AUTOSAR XML (schema 4-0-3)
standard types defined: Boolean, uint8, UInt16, UInt32, UInt8
package /AUTOSAR_Platform/DataConstrs
  range DC_Boolean: raw 0..1
  range DC_UInt16: raw 0..65535
  range DC_UInt8: raw 0..255
package /PATAC/Facility/DataTypes/Implementation
  compu method COMPU_Boolean: 0=FALSE, 1=TRUE
  unit NoUnit: factor-si-to-unit=1, offset-si-to-unit=0
package /PATAC/MSM/ComponentTypes
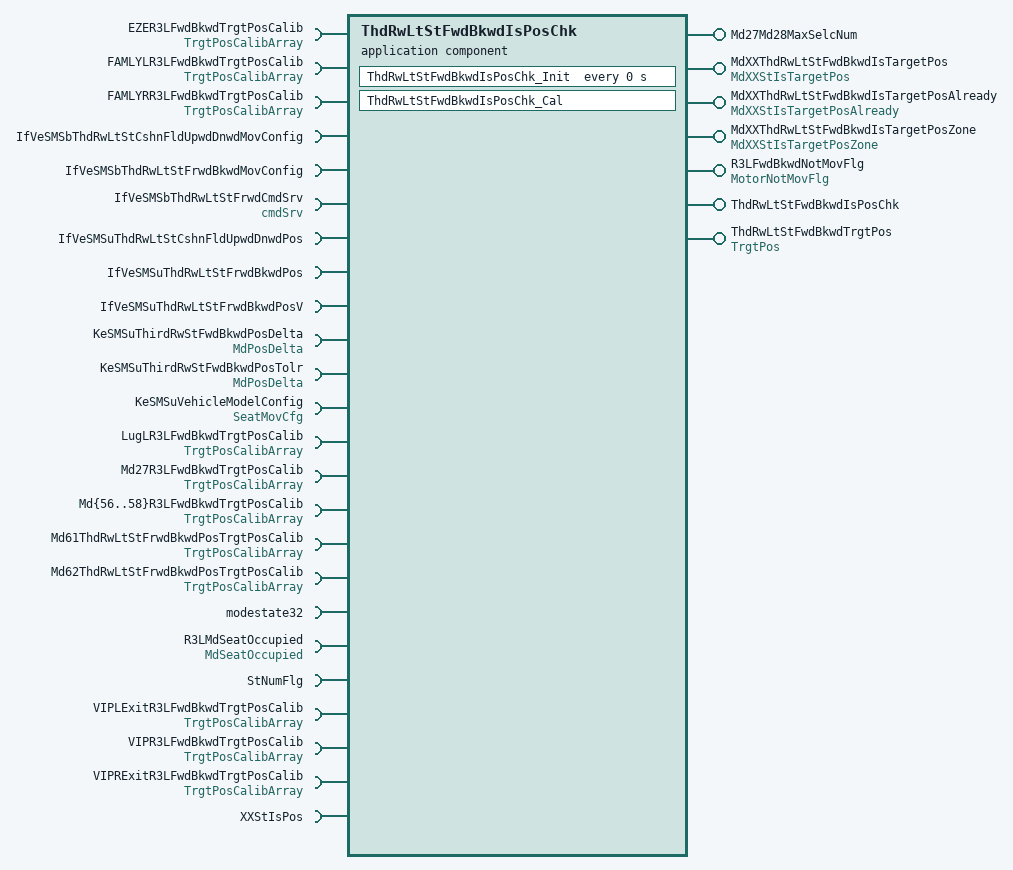
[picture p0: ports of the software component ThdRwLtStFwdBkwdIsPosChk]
  application sw component type ThdRwLtStFwdBkwdIsPosChk
    7 x provide port:
      Md27Md28MaxSelcNum: nonqueued-sender-com-spec{data-element=Md27Md28MaxSelcNum/Val, init-value=0}, provided-interface=Md27Md28MaxSelcNum
      MdXXThdRwLtStFwdBkwdIsTargetPos: nonqueued-sender-com-spec=data-element=MdXXStIsTargetPos/Val, provided-interface=MdXXStIsTargetPos
      MdXXThdRwLtStFwdBkwdIsTargetPosAlready: nonqueued-sender-com-spec=data-element=MdXXStIsTargetPosAlready/Val, provided-interface=MdXXStIsTargetPosAlready
      MdXXThdRwLtStFwdBkwdIsTargetPosZone: nonqueued-sender-com-spec=data-element=MdXXStIsTargetPosZone/Val, provided-interface=MdXXStIsTargetPosZone
      R3LFwdBkwdNotMovFlg: nonqueued-sender-com-spec{data-element=MotorNotMovFlg/Val, init-value=0}, provided-interface=MotorNotMovFlg
      ThdRwLtStFwdBkwdIsPosChk: server-com-spec{operation=Cal, queue-length=1}, provided-interface=ThdRwLtStFwdBkwdIsPosChk
      ThdRwLtStFwdBkwdTrgtPos: nonqueued-sender-com-spec{data-element=TrgtPos/Val, init-value=4095}, provided-interface=TrgtPos
    26 x require port:
      EZER3LFwdBkwdTrgtPosCalib: nonqueued-receiver-com-spec{data-element=TrgtPosArray, filter=data-filter-type=ALWAYS, init-value=[4095, 4095, 4095]}, required-interface=TrgtPosCalibArray
      FAMLYLR3LFwdBkwdTrgtPosCalib: nonqueued-receiver-com-spec{data-element=TrgtPosArray, filter=data-filter-type=ALWAYS, init-value=[4095, 4095, 4095]}, required-interface=TrgtPosCalibArray
      FAMLYRR3LFwdBkwdTrgtPosCalib: nonqueued-receiver-com-spec{data-element=TrgtPosArray, filter=data-filter-type=ALWAYS, init-value=[4095, 4095, 4095]}, required-interface=TrgtPosCalibArray
      IfVeSMSbThdRwLtStCshnFldUpwdDnwdMovConfig: nonqueued-receiver-com-spec{data-element=IfVeSMSbThdRwLtStCshnFldUpwdDnwdMovConfig/Val, filter=data-filter-type=ALWAYS, init-value=0}, required-interface=IfVeSMSbThdRwLtStCshnFldUpwdDnwdMovConfig
      IfVeSMSbThdRwLtStFrwdBkwdMovConfig: nonqueued-receiver-com-spec{data-element=IfVeSMSbThdRwLtStFrwdBkwdMovConfig/Val, filter=data-filter-type=ALWAYS, init-value=0}, required-interface=IfVeSMSbThdRwLtStFrwdBkwdMovConfig
      IfVeSMSbThdRwLtStFrwdCmdSrv: nonqueued-receiver-com-spec{data-element=cmdSrv/Val, filter=data-filter-type=ALWAYS, init-value=1}, required-interface=cmdSrv
      IfVeSMSuThdRwLtStCshnFldUpwdDnwdPos: nonqueued-receiver-com-spec{data-element=IfVeSMSuThdRwLtStCshnFldUpwdDnwdPos/Val, filter=data-filter-type=ALWAYS, init-value=0}, required-interface=IfVeSMSuThdRwLtStCshnFldUpwdDnwdPos
      IfVeSMSuThdRwLtStFrwdBkwdPos: nonqueued-receiver-com-spec{data-element=IfVeSMSuThdRwLtStFrwdBkwdPos/Val, filter=data-filter-type=ALWAYS, init-value=0}, required-interface=IfVeSMSuThdRwLtStFrwdBkwdPos
      IfVeSMSuThdRwLtStFrwdBkwdPosV: nonqueued-receiver-com-spec{data-element=IfVeSMSuThdRwLtStFrwdBkwdPosV/Val, filter=data-filter-type=ALWAYS, init-value=0}, required-interface=IfVeSMSuThdRwLtStFrwdBkwdPosV
      KeSMSuThirdRwStFwdBkwdPosDelta: parameter-require-com-spec{init-value=150, parameter=MdPosDelta/Val}, required-interface=MdPosDelta
      KeSMSuThirdRwStFwdBkwdPosTolr: parameter-require-com-spec{init-value=150, parameter=MdPosDelta/Val}, required-interface=MdPosDelta
      KeSMSuVehicleModelConfig: parameter-require-com-spec{init-value=2, parameter=SeatMovCfg/Val}, required-interface=SeatMovCfg
      LugLR3LFwdBkwdTrgtPosCalib: nonqueued-receiver-com-spec{data-element=TrgtPosArray, filter=data-filter-type=ALWAYS, init-value=[4095, 4095, 4095]}, required-interface=TrgtPosCalibArray
      Md27R3LFwdBkwdTrgtPosCalib: nonqueued-receiver-com-spec{data-element=TrgtPosArray, filter=data-filter-type=ALWAYS, init-value=[4095, 4095, 4095]}, required-interface=TrgtPosCalibArray
      Md{56..58}R3LFwdBkwdTrgtPosCalib: nonqueued-receiver-com-spec{data-element=TrgtPosArray, filter=data-filter-type=ALWAYS, init-value=[4095, 4095, 4095]}, required-interface=TrgtPosCalibArray
      Md61ThdRwLtStFrwdBkwdPosTrgtPosCalib: nonqueued-receiver-com-spec{data-element=TrgtPosArray, filter=data-filter-type=ALWAYS, init-value=[4095, 4095, 4095]}, required-interface=TrgtPosCalibArray
      Md62ThdRwLtStFrwdBkwdPosTrgtPosCalib: nonqueued-receiver-com-spec{data-element=TrgtPosArray, filter=data-filter-type=ALWAYS, init-value=[4095, 4095, 4095]}, required-interface=TrgtPosCalibArray
      modestate32: nonqueued-receiver-com-spec{data-element=modestate32/Val, filter=data-filter-type=ALWAYS, init-value=0}, required-interface=modestate32
      R3LMdSeatOccupied: nonqueued-receiver-com-spec{data-element=MdSeatOccupied/Val, filter=data-filter-type=ALWAYS, init-value=0}, required-interface=MdSeatOccupied
      StNumFlg: required-interface=StNumFlg
        required-com-specs:
          data-element=Is4s, filter=data-filter-type=ALWAYS, init-value=0
          data-element=Is6s, filter=data-filter-type=ALWAYS, init-value=0
          data-element=Is6s7s, filter=data-filter-type=ALWAYS, init-value=0
          data-element=Is7s, filter=data-filter-type=ALWAYS, init-value=0
      VIPLExitR3LFwdBkwdTrgtPosCalib: nonqueued-receiver-com-spec{data-element=TrgtPosArray, filter=data-filter-type=ALWAYS, init-value=[4095, 4095, 4095]}, required-interface=TrgtPosCalibArray
      VIPR3LFwdBkwdTrgtPosCalib: nonqueued-receiver-com-spec{data-element=TrgtPosArray, filter=data-filter-type=ALWAYS, init-value=[4095, 4095, 4095]}, required-interface=TrgtPosCalibArray
      VIPRExitR3LFwdBkwdTrgtPosCalib: nonqueued-receiver-com-spec{data-element=TrgtPosArray, filter=data-filter-type=ALWAYS, init-value=[4095, 4095, 4095]}, required-interface=TrgtPosCalibArray
      XXStIsPos: client-com-spec=Get, required-interface=XXStIsPos
    behavior ThdRwLtStFwdBkwdIsPosChk_InternalBehavior
      operation invoked event OIT_ThdRwLtStFwdBkwdIsPosChk_Cal_ThdRwLtStFwdBkwdIsPosChk_Cal: start-on-event=ThdRwLtStFwdBkwdIsPosChk_Cal, operation=ThdRwLtStFwdBkwdIsPosChk.Cal
      timing event ThdRwLtStFwdBkwdIsPosChk_InitEvent: start-on-event=ThdRwLtStFwdBkwdIsPosChk_Init, period=0
      runnable ThdRwLtStFwdBkwdIsPosChk_Cal
        data-receive-point-by-arguments:
          25 x access:
            REC_EZER3LFwdBkwdTrgtPosCalib_TrgtPosArray: accessed-variable=EZER3LFwdBkwdTrgtPosCalib.TrgtPosArray
            REC_FAMLYLR3LFwdBkwdTrgtPosCalib_TrgtPosArray: accessed-variable=FAMLYLR3LFwdBkwdTrgtPosCalib.TrgtPosArray
            REC_FAMLYRR3LFwdBkwdTrgtPosCalib_TrgtPosArray: accessed-variable=FAMLYRR3LFwdBkwdTrgtPosCalib.TrgtPosArray
            REC_IfVeSMSbThdRwLtStCshnFldUpwdDnwdMovConfig_Val: accessed-variable=IfVeSMSbThdRwLtStCshnFldUpwdDnwdMovConfig.Val
            REC_IfVeSMSbThdRwLtStFrwdBkwdMovConfig_Val: accessed-variable=IfVeSMSbThdRwLtStFrwdBkwdMovConfig.Val
            REC_IfVeSMSbThdRwLtStFrwdCmdSrv_Val: accessed-variable=IfVeSMSbThdRwLtStFrwdCmdSrv.Val
            REC_IfVeSMSuThdRwLtStCshnFldUpwdDnwdPos_Val: accessed-variable=IfVeSMSuThdRwLtStCshnFldUpwdDnwdPos.Val
            REC_IfVeSMSuThdRwLtStFrwdBkwdPos_Val: accessed-variable=IfVeSMSuThdRwLtStFrwdBkwdPos.Val
            REC_IfVeSMSuThdRwLtStFrwdBkwdPosV_Val: accessed-variable=IfVeSMSuThdRwLtStFrwdBkwdPosV.Val
            REC_LugLR3LFwdBkwdTrgtPosCalib_TrgtPosArray: accessed-variable=LugLR3LFwdBkwdTrgtPosCalib.TrgtPosArray
            REC_Md27R3LFwdBkwdTrgtPosCalib_TrgtPosArray: accessed-variable=Md27R3LFwdBkwdTrgtPosCalib.TrgtPosArray
            REC_Md{56..58}R3LFwdBkwdTrgtPosCalib_TrgtPosArray: accessed-variable=Md{56..58}R3LFwdBkwdTrgtPosCalib.TrgtPosArray
            REC_Md61ThdRwLtStFrwdBkwdPosTrgtPosCalib_TrgtPosArray: accessed-variable=Md61ThdRwLtStFrwdBkwdPosTrgtPosCalib.TrgtPosArray
            REC_Md62ThdRwLtStFrwdBkwdPosTrgtPosCalib_TrgtPosArray: accessed-variable=Md62ThdRwLtStFrwdBkwdPosTrgtPosCalib.TrgtPosArray
            REC_modestate32_Val: accessed-variable=modestate32.Val
            REC_R3LMdSeatOccupied_Val: accessed-variable=R3LMdSeatOccupied.Val
            REC_StNumFlg_Is4s: accessed-variable=StNumFlg.Is4s
            REC_StNumFlg_Is6s: accessed-variable=StNumFlg.Is6s
            REC_StNumFlg_Is6s7s: accessed-variable=StNumFlg.Is6s7s
            REC_StNumFlg_Is7s: accessed-variable=StNumFlg.Is7s
            REC_VIPLExitR3LFwdBkwdTrgtPosCalib_TrgtPosArray: accessed-variable=VIPLExitR3LFwdBkwdTrgtPosCalib.TrgtPosArray
            REC_VIPR3LFwdBkwdTrgtPosCalib_TrgtPosArray: accessed-variable=VIPR3LFwdBkwdTrgtPosCalib.TrgtPosArray
            REC_VIPRExitR3LFwdBkwdTrgtPosCalib_TrgtPosArray: accessed-variable=VIPRExitR3LFwdBkwdTrgtPosCalib.TrgtPosArray
        data-send-points:
          6 x access:
            SEND_Md27Md28MaxSelcNum_Val: accessed-variable=Md27Md28MaxSelcNum.Val
            SEND_MdXXThdRwLtStFwdBkwdIsTargetPos_Val: accessed-variable=MdXXThdRwLtStFwdBkwdIsTargetPos.Val
            SEND_MdXXThdRwLtStFwdBkwdIsTargetPosAlready_Val: accessed-variable=MdXXThdRwLtStFwdBkwdIsTargetPosAlready.Val
            SEND_MdXXThdRwLtStFwdBkwdIsTargetPosZone_Val: accessed-variable=MdXXThdRwLtStFwdBkwdIsTargetPosZone.Val
            SEND_R3LFwdBkwdNotMovFlg_Val: accessed-variable=R3LFwdBkwdNotMovFlg.Val
            SEND_ThdRwLtStFwdBkwdTrgtPos_Val: accessed-variable=ThdRwLtStFwdBkwdTrgtPos.Val
        parameter access PA_KeSMSuThirdRwStFwdBkwdPosDelta_Val: accessed-parameter=KeSMSuThirdRwStFwdBkwdPosDelta.Val
        parameter access PA_KeSMSuThirdRwStFwdBkwdPosTolr_Val: accessed-parameter=KeSMSuThirdRwStFwdBkwdPosTolr.Val
        parameter access PA_KeSMSuVehicleModelConfig_Val: accessed-parameter=KeSMSuVehicleModelConfig.Val
        sync call SC_XXStIsPos_Get: operation=XXStIsPos.Get, timeout=0
      runnable ThdRwLtStFwdBkwdIsPosChk_Init
        parameter access PA_KeSMSuThirdRwStFwdBkwdPosDelta_Val: accessed-parameter=KeSMSuThirdRwStFwdBkwdPosDelta.Val
        parameter access PA_KeSMSuThirdRwStFwdBkwdPosTolr_Val: accessed-parameter=KeSMSuThirdRwStFwdBkwdPosTolr.Val
        parameter access PA_KeSMSuVehicleModelConfig_Val: accessed-parameter=KeSMSuVehicleModelConfig.Val
  swc implementation ThdRwLtStFwdBkwdIsPosChk_Implementation: behavior=ThdRwLtStFwdBkwdIsPosChk_InternalBehavior
    code-descriptors:
      code Default: artifact-descriptors=autosar-engineering-object={short-label=Default, category=SWSRC}
package /PATAC/MSM/DataTypes
  parameter interface SeatMovCfg
    parameter data prototype Val: sw-calibration-access=READ-WRITE, type=UInt8
package /PATAC/MSM/Intervene/PortInterfaces
  sender receiver interface cmdSrv: invalidation-policy{data-element=cmdSrv/Val, handle-invalid=DONT-INVALIDATE}
    data Val: type=Implementation/Boolean
package /PATAC/MSM/ModeAdjust/CalPortInterface
  parameter interface MdPosDelta
    parameter data prototype Val: sw-calibration-access=READ-WRITE, type=UInt16
package /PATAC/MSM/ModeAdjust/DataType
  impl type TrgtPosCalibArray: category=ARRAY, sw-calibration-access=READ-ONLY, type-emitter=RTE  # 0:pos 1:max 2:min
    element Element: array-size=3, array-size-semantics=FIXED-SIZE, implementation-data-type=UInt16, invalid-value=0
package /PATAC/MSM/ModeAdjust/Interfaces
  sender receiver interface IfVeSMSuThdRwLtStCshnFldUpwdDnwdPos: invalidation-policy{data-element=IfVeSMSuThdRwLtStCshnFldUpwdDnwdPos/Val, handle-invalid=DONT-INVALIDATE}
    data Val: type=UInt16
  sender receiver interface IfVeSMSuThdRwLtStFrwdBkwdPosV: invalidation-policy{data-element=IfVeSMSuThdRwLtStFrwdBkwdPosV/Val, handle-invalid=DONT-INVALIDATE}
    data Val: type=Implementation/Boolean
package /PATAC/MSM/ModeAdjust/PortInterface
  client server interface ThdRwLtStFwdBkwdIsPosChk
    operation Cal
  client server interface XXStIsPos
    operation Get
      8 x arg, all with server-argument-impl-policy=USE-ARGUMENT-TYPE:
        PosV: type=DataTypes/Boolean, direction=IN
        Pos: type=UInt16, direction=IN
        CalibArray: type=TrgtPosCalibArray, direction=IN
        Delta: type=UInt16, direction=IN
        Tolr: type=UInt16, direction=IN
        IsPos: type=DataTypes/Boolean, direction=OUT
        IsPosZone: type=DataTypes/Boolean, direction=OUT
        IsPosAlready: type=DataTypes/Boolean, direction=OUT
  9 x sender receiver interface:
    Md27Md28MaxSelcNum: invalidation-policy{data-element=Md27Md28MaxSelcNum/Val, handle-invalid=DONT-INVALIDATE}
      data Val: type=UInt8
    MdSeatOccupied: invalidation-policy{data-element=MdSeatOccupied/Val, handle-invalid=DONT-INVALIDATE}
      data Val: type=Implementation/Boolean
    MdXXStIsTargetPos: invalidation-policy{data-element=MdXXStIsTargetPos/Val, handle-invalid=DONT-INVALIDATE}
      data Val: type=UInt32
    MdXXStIsTargetPosAlready: invalidation-policy{data-element=MdXXStIsTargetPosAlready/Val, handle-invalid=DONT-INVALIDATE}
      data Val: type=UInt32
    MdXXStIsTargetPosZone: invalidation-policy{data-element=MdXXStIsTargetPosZone/Val, handle-invalid=DONT-INVALIDATE}
      data Val: type=UInt32
    modestate32: invalidation-policy{data-element=modestate32/Val, handle-invalid=DONT-INVALIDATE}
      data Val: type=UInt32
    MotorNotMovFlg: invalidation-policy{data-element=MotorNotMovFlg/Val, handle-invalid=DONT-INVALIDATE}
      data Val: type=Implementation/Boolean
    StNumFlg
      4 x data, all with type=Implementation/Boolean:
        Is4s
        Is6s
        Is6s7s
        Is7s
      invalidation-policys:
        data-element=Is4s, handle-invalid=DONT-INVALIDATE
        data-element=Is6s, handle-invalid=DONT-INVALIDATE
        data-element=Is6s7s, handle-invalid=DONT-INVALIDATE
        data-element=Is7s, handle-invalid=DONT-INVALIDATE
    TrgtPosCalibArray: invalidation-policy{data-element=TrgtPosArray, handle-invalid=DONT-INVALIDATE}
      data TrgtPosArray: type=TrgtPosCalibArray  # 0:Pos 1:Max 2:Min
package /PATAC/MSM/PortInterfaces
  4 x sender receiver interface:
    IfVeSMSbThdRwLtStCshnFldUpwdDnwdMovConfig: invalidation-policy{data-element=IfVeSMSbThdRwLtStCshnFldUpwdDnwdMovConfig/Val, handle-invalid=DONT-INVALIDATE}
      data Val: type=Implementation/Boolean
    IfVeSMSbThdRwLtStFrwdBkwdMovConfig: invalidation-policy{data-element=IfVeSMSbThdRwLtStFrwdBkwdMovConfig/Val, handle-invalid=DONT-INVALIDATE}
      data Val: type=Implementation/Boolean
    IfVeSMSuThdRwLtStFrwdBkwdPos: invalidation-policy{data-element=IfVeSMSuThdRwLtStFrwdBkwdPos/Val, handle-invalid=DONT-INVALIDATE}
      data Val: type=UInt16
    TrgtPos: invalidation-policy{data-element=TrgtPos/Val, handle-invalid=DONT-INVALIDATE}
      data Val: type=UInt16
